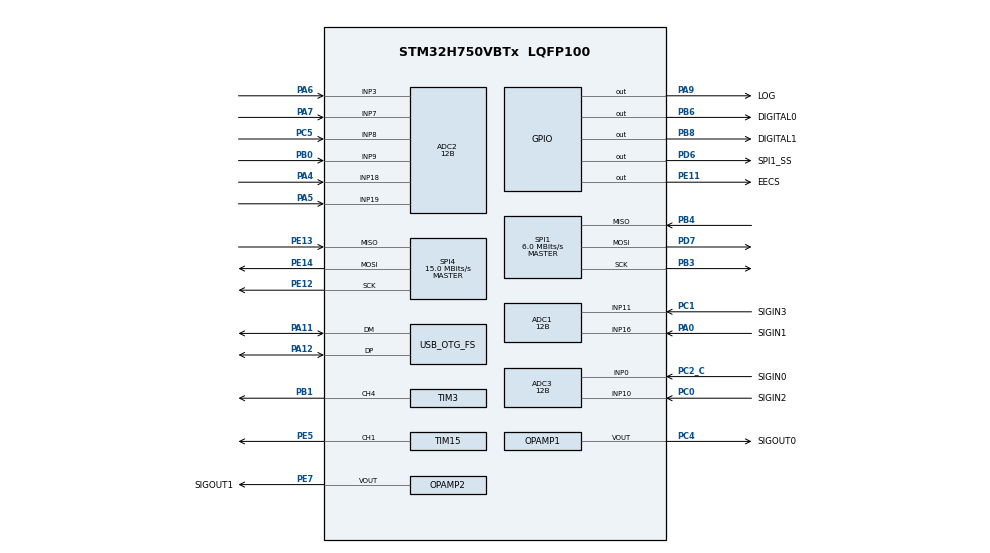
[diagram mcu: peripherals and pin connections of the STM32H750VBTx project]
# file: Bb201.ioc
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ADC1.Channel-0\#ChannelRegularConversion=ADC_CHANNEL_16
ADC1.Channel-3\#ChannelRegularConversion=ADC_CHANNEL_11
ADC1.ContinuousConvMode=DISABLE
ADC1.ConversionDataManagement=ADC_CONVERSIONDATA_DMA_CIRCULAR
ADC1.EOCSelection=ADC_EOC_SEQ_CONV
ADC1.ExternalTrigConv=ADC_EXTERNALTRIG_T6_TRGO
ADC1.NbrOfConversion=2
ADC1.NbrOfConversionFlag=1
ADC1.OffsetNumber-0\#ChannelRegularConversion=ADC_OFFSET_NONE
ADC1.OffsetNumber-3\#ChannelRegularConversion=ADC_OFFSET_NONE
ADC1.OffsetSignedSaturation-0\#ChannelRegularConversion=DISABLE
ADC1.Rank-0\#ChannelRegularConversion=1
ADC1.Rank-3\#ChannelRegularConversion=2
ADC1.Resolution=ADC_RESOLUTION_12B
ADC1.SamplingTime-0\#ChannelRegularConversion=ADC_SAMPLETIME_1CYCLE_5
ADC1.SamplingTime-3\#ChannelRegularConversion=ADC_SAMPLETIME_1CYCLE_5
ADC1.master=1
ADC2.Channel-0\#ChannelRegularConversion=ADC_CHANNEL_18
ADC2.Channel-1\#ChannelRegularConversion=ADC_CHANNEL_19
ADC2.Channel-2\#ChannelRegularConversion=ADC_CHANNEL_3
ADC2.Channel-3\#ChannelRegularConversion=ADC_CHANNEL_7
ADC2.Channel-4\#ChannelRegularConversion=ADC_CHANNEL_8
ADC2.Channel-5\#ChannelRegularConversion=ADC_CHANNEL_9
ADC2.ContinuousConvMode=DISABLE
ADC2.ConversionDataManagement=ADC_CONVERSIONDATA_DMA_CIRCULAR
ADC2.EOCSelection=ADC_EOC_SEQ_CONV
ADC2.ExternalTrigConv=ADC_EXTERNALTRIG_LPTIM3_OUT
ADC2.NbrOfConversion=6
ADC2.NbrOfConversionFlag=1
ADC2.OffsetNumber-0\#ChannelRegularConversion=ADC_OFFSET_NONE
ADC2.OffsetNumber-1\#ChannelRegularConversion=ADC_OFFSET_NONE
ADC2.OffsetNumber-2\#ChannelRegularConversion=ADC_OFFSET_NONE
ADC2.OffsetNumber-3\#ChannelRegularConversion=ADC_OFFSET_NONE
ADC2.OffsetNumber-4\#ChannelRegularConversion=ADC_OFFSET_NONE
ADC2.OffsetNumber-5\#ChannelRegularConversion=ADC_OFFSET_NONE
ADC2.OffsetSignedSaturation-0\#ChannelRegularConversion=DISABLE
ADC2.OffsetSignedSaturation-1\#ChannelRegularConversion=DISABLE
ADC2.OffsetSignedSaturation-2\#ChannelRegularConversion=DISABLE
ADC2.OffsetSignedSaturation-3\#ChannelRegularConversion=DISABLE
ADC2.OffsetSignedSaturation-4\#ChannelRegularConversion=DISABLE
ADC2.OffsetSignedSaturation-5\#ChannelRegularConversion=DISABLE
ADC2.OversamplingMode=DISABLE
ADC2.Rank-0\#ChannelRegularConversion=1
ADC2.Rank-1\#ChannelRegularConversion=2
ADC2.Rank-2\#ChannelRegularConversion=3
ADC2.Rank-3\#ChannelRegularConversion=4
ADC2.Rank-4\#ChannelRegularConversion=5
ADC2.Rank-5\#ChannelRegularConversion=6
ADC2.Resolution=ADC_RESOLUTION_12B
ADC2.SamplingTime-0\#ChannelRegularConversion=ADC_SAMPLETIME_2CYCLES_5
ADC2.SamplingTime-1\#ChannelRegularConversion=ADC_SAMPLETIME_2CYCLES_5
ADC2.SamplingTime-2\#ChannelRegularConversion=ADC_SAMPLETIME_2CYCLES_5
ADC2.SamplingTime-3\#ChannelRegularConversion=ADC_SAMPLETIME_2CYCLES_5
ADC2.SamplingTime-4\#ChannelRegularConversion=ADC_SAMPLETIME_2CYCLES_5
ADC2.SamplingTime-5\#ChannelRegularConversion=ADC_SAMPLETIME_2CYCLES_5
ADC3.Channel-0\#ChannelRegularConversion=ADC_CHANNEL_0
ADC3.Channel-3\#ChannelRegularConversion=ADC_CHANNEL_10
ADC3.ClockPrescaler=ADC_CLOCK_ASYNC_DIV1
ADC3.ContinuousConvMode=DISABLE
ADC3.ConversionDataManagement=ADC_CONVERSIONDATA_DMA_CIRCULAR
ADC3.EOCSelection=ADC_EOC_SEQ_CONV
ADC3.ExternalTrigConv=ADC_EXTERNALTRIG_T4_TRGO
ADC3.NbrOfConversion=2
ADC3.NbrOfConversionFlag=1
ADC3.OffsetNumber-0\#ChannelRegularConversion=ADC_OFFSET_NONE
ADC3.OffsetNumber-3\#ChannelRegularConversion=ADC_OFFSET_NONE
ADC3.OffsetSignedSaturation-0\#ChannelRegularConversion=DISABLE
ADC3.OversamplingMode=DISABLE
ADC3.Rank-0\#ChannelRegularConversion=1
ADC3.Rank-3\#ChannelRegularConversion=2
ADC3.Resolution=ADC_RESOLUTION_12B
ADC3.SamplingTime-0\#ChannelRegularConversion=ADC_SAMPLETIME_1CYCLE_5
ADC3.SamplingTime-3\#ChannelRegularConversion=ADC_SAMPLETIME_1CYCLE_5
ARM.CMSIS.5.7.0.CMSISJjCORE=true
ARM.CMSIS.5.7.0.CMSISJjDSP=Library
CORTEX_M7.AccessPermission-Cortex_Memory_Protection_Unit_Region0_Settings=MPU_REGION_FULL_ACCESS
CORTEX_M7.BaseAddress-Cortex_Memory_Protection_Unit_Region0_Settings=0x38000000
CORTEX_M7.CPU_DCache=Enabled
CORTEX_M7.CPU_ICache=Enabled
CORTEX_M7.DisableExec-Cortex_Memory_Protection_Unit_Region0_Settings=MPU_INSTRUCTION_ACCESS_DISABLE
CORTEX_M7.Enable-Cortex_Memory_Protection_Unit_Region0_Settings=MPU_REGION_ENABLE
CORTEX_M7.IsBufferable-Cortex_Memory_Protection_Unit_Region0_Settings=MPU_ACCESS_NOT_BUFFERABLE
CORTEX_M7.IsShareable-Cortex_Memory_Protection_Unit_Region0_Settings=MPU_ACCESS_NOT_SHAREABLE
CORTEX_M7.MPU_Control=MPU_PRIVILEGED_DEFAULT
CORTEX_M7.Size-Cortex_Memory_Protection_Unit_Region0_Settings=MPU_REGION_SIZE_64KB
DAC1.DAC_Channel-DAC_OUT2_Int=DAC_CHANNEL_2
DAC1.DAC_SampleAndHold-DAC_OUT1_Int=DAC_SAMPLEANDHOLD_DISABLE
DAC1.DAC_Trigger-DAC_OUT1_Int=DAC_TRIGGER_T4_TRGO
DAC1.DAC_Trigger-DAC_OUT2_Int=DAC_TRIGGER_T6_TRGO
DAC1.DAC_UserTrimming-DAC_OUT1_Int=DAC_TRIMMING_FACTORY
Dma.ADC1.0.Direction=DMA_PERIPH_TO_MEMORY
Dma.ADC1.0.EventEnable=DISABLE
Dma.ADC1.0.FIFOMode=DMA_FIFOMODE_DISABLE
Dma.ADC1.0.Instance=DMA2_Stream0
Dma.ADC1.0.MemDataAlignment=DMA_MDATAALIGN_HALFWORD
Dma.ADC1.0.MemInc=DMA_MINC_ENABLE
Dma.ADC1.0.Mode=DMA_CIRCULAR
Dma.ADC1.0.PeriphDataAlignment=DMA_PDATAALIGN_HALFWORD
Dma.ADC1.0.PeriphInc=DMA_PINC_DISABLE
Dma.ADC1.0.Polarity=HAL_DMAMUX_REQ_GEN_RISING
Dma.ADC1.0.Priority=DMA_PRIORITY_LOW
Dma.ADC1.0.RequestNumber=1
Dma.ADC1.0.SignalID=NONE
Dma.ADC1.0.SyncEnable=DISABLE
Dma.ADC1.0.SyncPolarity=HAL_DMAMUX_SYNC_NO_EVENT
Dma.ADC1.0.SyncRequestNumber=1
Dma.ADC1.0.SyncSignalID=NONE
Dma.ADC2.2.Direction=DMA_PERIPH_TO_MEMORY
Dma.ADC2.2.EventEnable=DISABLE
Dma.ADC2.2.FIFOMode=DMA_FIFOMODE_DISABLE
Dma.ADC2.2.Instance=DMA1_Stream2
Dma.ADC2.2.MemDataAlignment=DMA_MDATAALIGN_HALFWORD
Dma.ADC2.2.MemInc=DMA_MINC_ENABLE
Dma.ADC2.2.Mode=DMA_CIRCULAR
Dma.ADC2.2.PeriphDataAlignment=DMA_PDATAALIGN_HALFWORD
Dma.ADC2.2.PeriphInc=DMA_PINC_DISABLE
Dma.ADC2.2.Polarity=HAL_DMAMUX_REQ_GEN_RISING
Dma.ADC2.2.Priority=DMA_PRIORITY_LOW
Dma.ADC2.2.RequestNumber=1
Dma.ADC2.2.SignalID=NONE
Dma.ADC2.2.SyncEnable=DISABLE
Dma.ADC2.2.SyncPolarity=HAL_DMAMUX_SYNC_NO_EVENT
Dma.ADC2.2.SyncRequestNumber=1
Dma.ADC2.2.SyncSignalID=NONE
Dma.ADC3.3.Direction=DMA_PERIPH_TO_MEMORY
Dma.ADC3.3.EventEnable=DISABLE
Dma.ADC3.3.FIFOMode=DMA_FIFOMODE_DISABLE
Dma.ADC3.3.Instance=DMA1_Stream0
Dma.ADC3.3.MemDataAlignment=DMA_MDATAALIGN_HALFWORD
Dma.ADC3.3.MemInc=DMA_MINC_ENABLE
Dma.ADC3.3.Mode=DMA_CIRCULAR
Dma.ADC3.3.PeriphDataAlignment=DMA_PDATAALIGN_HALFWORD
Dma.ADC3.3.PeriphInc=DMA_PINC_DISABLE
Dma.ADC3.3.Polarity=HAL_DMAMUX_REQ_GEN_RISING
Dma.ADC3.3.Priority=DMA_PRIORITY_LOW
Dma.ADC3.3.RequestNumber=1
Dma.ADC3.3.SignalID=NONE
Dma.ADC3.3.SyncEnable=DISABLE
Dma.ADC3.3.SyncPolarity=HAL_DMAMUX_SYNC_NO_EVENT
Dma.ADC3.3.SyncRequestNumber=1
Dma.ADC3.3.SyncSignalID=NONE
Dma.DAC1_CH1.1.Direction=DMA_MEMORY_TO_PERIPH
Dma.DAC1_CH1.1.EventEnable=DISABLE
Dma.DAC1_CH1.1.FIFOMode=DMA_FIFOMODE_DISABLE
Dma.DAC1_CH1.1.Instance=DMA1_Stream1
Dma.DAC1_CH1.1.MemDataAlignment=DMA_MDATAALIGN_HALFWORD
Dma.DAC1_CH1.1.MemInc=DMA_MINC_ENABLE
Dma.DAC1_CH1.1.Mode=DMA_CIRCULAR
Dma.DAC1_CH1.1.PeriphDataAlignment=DMA_PDATAALIGN_HALFWORD
Dma.DAC1_CH1.1.PeriphInc=DMA_PINC_DISABLE
Dma.DAC1_CH1.1.Polarity=HAL_DMAMUX_REQ_GEN_RISING
Dma.DAC1_CH1.1.Priority=DMA_PRIORITY_LOW
Dma.DAC1_CH1.1.RequestNumber=1
Dma.DAC1_CH1.1.SignalID=NONE
Dma.DAC1_CH1.1.SyncEnable=DISABLE
Dma.DAC1_CH1.1.SyncPolarity=HAL_DMAMUX_SYNC_NO_EVENT
Dma.DAC1_CH1.1.SyncRequestNumber=1
Dma.DAC1_CH1.1.SyncSignalID=NONE
Dma.DAC1_CH2.4.Direction=DMA_MEMORY_TO_PERIPH
Dma.DAC1_CH2.4.EventEnable=DISABLE
Dma.DAC1_CH2.4.FIFOMode=DMA_FIFOMODE_DISABLE
Dma.DAC1_CH2.4.Instance=DMA2_Stream1
Dma.DAC1_CH2.4.MemDataAlignment=DMA_MDATAALIGN_HALFWORD
Dma.DAC1_CH2.4.MemInc=DMA_MINC_ENABLE
Dma.DAC1_CH2.4.Mode=DMA_CIRCULAR
Dma.DAC1_CH2.4.PeriphDataAlignment=DMA_PDATAALIGN_HALFWORD
Dma.DAC1_CH2.4.PeriphInc=DMA_PINC_DISABLE
Dma.DAC1_CH2.4.Polarity=HAL_DMAMUX_REQ_GEN_RISING
Dma.DAC1_CH2.4.Priority=DMA_PRIORITY_LOW
Dma.DAC1_CH2.4.RequestNumber=1
Dma.DAC1_CH2.4.SignalID=NONE
Dma.DAC1_CH2.4.SyncEnable=DISABLE
Dma.DAC1_CH2.4.SyncPolarity=HAL_DMAMUX_SYNC_NO_EVENT
Dma.DAC1_CH2.4.SyncRequestNumber=1
Dma.DAC1_CH2.4.SyncSignalID=NONE
Dma.Request0=ADC1
Dma.Request1=DAC1_CH1
Dma.Request2=ADC2
Dma.Request3=ADC3
Dma.Request4=DAC1_CH2
Dma.Request5=SPI4_RX
Dma.Request6=SPI4_TX
Dma.SPI4_RX.5.Direction=DMA_PERIPH_TO_MEMORY
Dma.SPI4_RX.5.EventEnable=DISABLE
Dma.SPI4_RX.5.FIFOMode=DMA_FIFOMODE_DISABLE
Dma.SPI4_RX.5.Instance=DMA1_Stream3
Dma.SPI4_RX.5.MemDataAlignment=DMA_MDATAALIGN_BYTE
Dma.SPI4_RX.5.MemInc=DMA_MINC_ENABLE
Dma.SPI4_RX.5.Mode=DMA_NORMAL
Dma.SPI4_RX.5.PeriphDataAlignment=DMA_PDATAALIGN_BYTE
Dma.SPI4_RX.5.PeriphInc=DMA_PINC_DISABLE
Dma.SPI4_RX.5.Polarity=HAL_DMAMUX_REQ_GEN_RISING
Dma.SPI4_RX.5.Priority=DMA_PRIORITY_LOW
Dma.SPI4_RX.5.RequestNumber=1
Dma.SPI4_RX.5.SignalID=NONE
Dma.SPI4_RX.5.SyncEnable=DISABLE
Dma.SPI4_RX.5.SyncPolarity=HAL_DMAMUX_SYNC_NO_EVENT
Dma.SPI4_RX.5.SyncRequestNumber=1
Dma.SPI4_RX.5.SyncSignalID=NONE
Dma.SPI4_TX.6.Direction=DMA_MEMORY_TO_PERIPH
Dma.SPI4_TX.6.EventEnable=DISABLE
Dma.SPI4_TX.6.FIFOMode=DMA_FIFOMODE_DISABLE
Dma.SPI4_TX.6.Instance=DMA1_Stream4
Dma.SPI4_TX.6.MemDataAlignment=DMA_MDATAALIGN_BYTE
Dma.SPI4_TX.6.MemInc=DMA_MINC_ENABLE
Dma.SPI4_TX.6.Mode=DMA_NORMAL
Dma.SPI4_TX.6.PeriphDataAlignment=DMA_PDATAALIGN_BYTE
Dma.SPI4_TX.6.PeriphInc=DMA_PINC_DISABLE
Dma.SPI4_TX.6.Polarity=HAL_DMAMUX_REQ_GEN_RISING
Dma.SPI4_TX.6.Priority=DMA_PRIORITY_LOW
Dma.SPI4_TX.6.RequestNumber=1
Dma.SPI4_TX.6.SignalID=NONE
Dma.SPI4_TX.6.SyncEnable=DISABLE
Dma.SPI4_TX.6.SyncPolarity=HAL_DMAMUX_SYNC_NO_EVENT
Dma.SPI4_TX.6.SyncRequestNumber=1
Dma.SPI4_TX.6.SyncSignalID=NONE
LPTIM3.ClockPrescaler=LPTIM_PRESCALER_DIV128
Mcu.Family=STM32H7
Mcu.Name=STM32H750VBTx
Mcu.Package=LQFP100
NVIC.DMA1_Stream0_IRQn=true\:0\:0\:false\:false\:true\:false\:true
NVIC.DMA1_Stream1_IRQn=true\:0\:0\:false\:false\:true\:false\:true
NVIC.DMA1_Stream2_IRQn=true\:0\:0\:false\:false\:true\:false\:true
NVIC.DMA1_Stream3_IRQn=true\:0\:0\:false\:false\:true\:false\:true
NVIC.DMA1_Stream4_IRQn=true\:0\:0\:false\:false\:true\:false\:true
NVIC.DMA2_Stream0_IRQn=true\:0\:0\:false\:false\:true\:false\:true
NVIC.DMA2_Stream1_IRQn=true\:0\:0\:false\:false\:true\:false\:true
NVIC.HASH_RNG_IRQn=true\:0\:0\:false\:false\:true\:true\:true
NVIC.OTG_FS_IRQn=true\:0\:0\:false\:false\:true\:false\:true
NVIC.PriorityGroup=NVIC_PRIORITYGROUP_4
NVIC.SPI4_IRQn=true\:0\:0\:false\:false\:true\:false\:true
NVIC.TIM15_IRQn=true\:0\:0\:false\:false\:true\:true\:true
NVIC.TIM7_IRQn=true\:0\:0\:false\:false\:true\:true\:true
OPAMP1.PowerMode=OPAMP_POWERMODE_HIGHSPEED
OPAMP1.SelfCalibration=Enable
OPAMP1.UserTrimming=OPAMP_TRIMMING_USER
OPAMP2.PowerMode=OPAMP_POWERMODE_HIGHSPEED
OPAMP2.SelfCalibration=Enable
OPAMP2.UserTrimming=OPAMP_TRIMMING_USER
PA0.GPIO_Label=SIGIN1
PA0.Mode=IN16-Single-Ended
PA0.Signal=ADC1_INP16
PA11.Mode=Device_Only
PA11.Signal=USB_OTG_FS_DM
PA12.Mode=Device_Only
PA12.Signal=USB_OTG_FS_DP
PA13\ (JTMS/SWDIO).Mode=Serial_Wire
PA13\ (JTMS/SWDIO).Signal=DEBUG_JTMS-SWDIO
PA14\ (JTCK/SWCLK).Mode=Serial_Wire
PA14\ (JTCK/SWCLK).Signal=DEBUG_JTCK-SWCLK
PA4.Signal=ADCx_INP18
PA5.Signal=ADCx_INP19
PA6.Signal=ADCx_INP3
PA7.Signal=ADCx_INP7
PA9.GPIO_Label=LOG
PA9.Signal=GPIO_Output
PB0.Signal=ADCx_INP9
PB1.Signal=S_TIM3_CH4
PB3\ (JTDO/TRACESWO).Mode=Full_Duplex_Master
PB3\ (JTDO/TRACESWO).Signal=SPI1_SCK
PB4\ (NJTRST).Mode=Full_Duplex_Master
PB4\ (NJTRST).Signal=SPI1_MISO
PB6.GPIO_Label=DIGITAL0
PB6.PinState=GPIO_PIN_SET
PB6.Signal=GPIO_Output
PB8.GPIO_Label=DIGITAL1
PB8.PinState=GPIO_PIN_SET
PB8.Signal=GPIO_Output
PC0.GPIO_Label=SIGIN2
PC0.Signal=ADCx_INP10
PC1.GPIO_Label=SIGIN3
PC1.Signal=ADCx_INP11
PC2_C.GPIO_Label=SIGIN0
PC2_C.Mode=IN0-Single-Ended
PC2_C.Signal=ADC3_INP0
PC4.GPIO_Label=SIGOUT0
PC4.Mode=Follower-DAC_OUT1-INP
PC4.Signal=OPAMP1_VOUT
PC5.Signal=ADCx_INP8
PD6.GPIO_Label=SPI1_SS
PD6.GPIO_PuPd=GPIO_PULLUP
PD6.GPIO_Speed=GPIO_SPEED_FREQ_HIGH
PD6.PinState=GPIO_PIN_SET
PD6.Signal=GPIO_Output
PD7.Mode=Full_Duplex_Master
PD7.Signal=SPI1_MOSI
PE11.GPIO_Label=EECS
PE11.Signal=GPIO_Output
PE12.Mode=Full_Duplex_Master
PE12.Signal=SPI4_SCK
PE13.Mode=Full_Duplex_Master
PE13.Signal=SPI4_MISO
PE14.Mode=Full_Duplex_Master
PE14.Signal=SPI4_MOSI
PE5.Signal=S_TIM15_CH1
PE7.GPIO_Label=SIGOUT1
PE7.Mode=Follower-DAC_OUT2-INP
PE7.Signal=OPAMP2_VOUT
PH0-OSC_IN\ (PH0).Mode=HSE-External-Oscillator
PH0-OSC_IN\ (PH0).Signal=RCC_OSC_IN
PH1-OSC_OUT\ (PH1).Mode=HSE-External-Oscillator
PH1-OSC_OUT\ (PH1).Signal=RCC_OSC_OUT
ProjectManager.HeapSize=0x200
ProjectManager.StackSize=0x400
ProjectManager.TargetToolchain=STM32CubeIDE
RCC.ADCCLockSelection=RCC_ADCCLKSOURCE_PLL3
RCC.ADCFreq_Value=40000000
RCC.APB1Freq_Value=120000000
RCC.APB2Freq_Value=120000000
RCC.APB3Freq_Value=120000000
RCC.APB4Freq_Value=120000000
RCC.CKPERSourceSelection=RCC_CLKPSOURCE_HSE
RCC.CortexFreq_Value=480000000
RCC.D1PPRE=RCC_APB3_DIV2
RCC.D2PPRE1=RCC_APB1_DIV2
RCC.D2PPRE2=RCC_APB2_DIV2
RCC.D3PPRE=RCC_APB4_DIV2
RCC.DIVM1=2
RCC.DIVM2=9
RCC.DIVM3=12
RCC.DIVN1=80
RCC.DIVN2=265
RCC.DIVN3=80
RCC.DIVP2=4
RCC.DIVQ1=20
RCC.DIVQ3=4
RCC.DIVR3=4
RCC.HCLKFreq_Value=240000000
RCC.HPRE=RCC_HCLK_DIV2
RCC.HSE_VALUE=24000000
RCC.LPTIM1CLockSelection=RCC_LPTIM1CLKSOURCE_CLKP
RCC.LPTIM2CLockSelection=RCC_LPTIM2CLKSOURCE_PLL2
RCC.LPTIM345CLockSelection=RCC_LPTIM345CLKSOURCE_PLL3
RCC.PLL2FRACN=4096
RCC.PLLFRACN=0
RCC.PLLSourceVirtual=RCC_PLLSOURCE_HSE
RCC.SPI123CLockSelection=RCC_SPI123CLKSOURCE_CLKP
RCC.SYSCLKFreq_VALUE=480000000
RCC.SYSCLKSource=RCC_SYSCLKSOURCE_PLLCLK
RCC.USBCLockSelection=RCC_USBCLKSOURCE_HSI48
RCC.USBFreq_Value=48000000
RNG.ClockErrorDetection=RNG_CED_DISABLE
SH.ADCx_INP10.0=ADC3_INP10,IN10-Single-Ended
SH.ADCx_INP11.0=ADC1_INP11,IN11-Single-Ended
SH.ADCx_INP18.0=ADC2_INP18,IN18-Single-Ended
SH.ADCx_INP19.0=ADC2_INP19,IN19-Single-Ended
SH.ADCx_INP3.0=ADC2_INP3,IN3-Single-Ended
SH.ADCx_INP7.0=ADC2_INP7,IN7-Single-Ended
SH.ADCx_INP8.0=ADC2_INP8,IN8-Single-Ended
SH.ADCx_INP9.0=ADC2_INP9,IN9-Single-Ended
SH.S_TIM15_CH1.0=TIM15_CH1,PWM Generation1 CH1
SH.S_TIM3_CH4.0=TIM3_CH4,PWM Generation4 CH4
SPI1.BaudRatePrescaler=SPI_BAUDRATEPRESCALER_4
SPI1.CalculateBaudRate=6.0 MBits/s
SPI1.DataSize=SPI_DATASIZE_8BIT
SPI1.Direction=SPI_DIRECTION_2LINES
SPI1.Mode=SPI_MODE_MASTER
SPI1.VirtualType=VM_MASTER
SPI4.BaudRatePrescaler=SPI_BAUDRATEPRESCALER_8
SPI4.CalculateBaudRate=15.0 MBits/s
SPI4.DataSize=SPI_DATASIZE_8BIT
SPI4.Direction=SPI_DIRECTION_2LINES
SPI4.Mode=SPI_MODE_MASTER
SPI4.VirtualType=VM_MASTER
TIM15.Channel-PWM\ Generation1\ CH1=TIM_CHANNEL_1
TIM15.Period=4000
TIM15.Prescaler=48000
TIM15.Pulse-PWM\ Generation1\ CH1=3800
TIM3.Channel-PWM\ Generation4\ CH4=TIM_CHANNEL_4
TIM3.Period=20000
TIM3.Prescaler=200
TIM3.Pulse-PWM\ Generation4\ CH4=10000
TIM4.Period=2500
TIM4.TIM_MasterOutputTrigger=TIM_TRGO_UPDATE
TIM6.Period=2500
TIM6.TIM_MasterOutputTrigger=TIM_TRGO_UPDATE
TIM7.Period=1000
TIM7.Prescaler=240
USB_DEVICE.CLASS_NAME_FS=CDC
USB_DEVICE.VirtualMode-CDC_FS=Cdc
USB_DEVICE.VirtualModeFS=Cdc_FS
USB_OTG_FS.VirtualMode=Device_Only
VP_ARM.CMSIS_VS_CMSISJjDSP_1.8.0_5.7.0.Mode=CMSISJjDSP
VP_DAC1_VS_DACI1.Mode=DAC_OUT1_Int
VP_DAC1_VS_DACI2.Mode=DAC_OUT2_Int
VP_LPTIM3_VS_LPTIM_counterModeInternalClock.Mode=Counts__internal_clock_event_00
VP_RNG_VS_RNG.Mode=RNG_Activate
VP_TIM4_VS_ClockSourceINT.Mode=Internal
VP_TIM6_VS_ClockSourceINT.Mode=Enable_Timer
VP_TIM7_VS_ClockSourceINT.Mode=Enable_Timer
VP_USB_DEVICE_VS_USB_DEVICE_CDC_FS.Mode=CDC_FS
board=custom

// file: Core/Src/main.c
/* USER CODE BEGIN Header */
/**
  ******************************************************************************
  * @file           : main.c
  * @brief          : Main program body
  ******************************************************************************
  * @attention
  *
  * <h2><center>&copy; Copyright (c) 2020 STMicroelectronics.
  * All rights reserved.</center></h2>
  *
  * This software component is licensed by ST under Ultimate Liberty license
  * SLA0044, the "License"; You may not use this file except in compliance with
  * the License. You may obtain a copy of the License at:
  *                             www.st.com/SLA0044
  *
  ******************************************************************************
  */
/* USER CODE END Header */
#include "main.h"
#include "usb_device.h"

/* USER CODE BEGIN Includes */
#include "usb_midi.h"
#include "fir.h"

/* USER CODE END Includes */

ADC_HandleTypeDef hadc1;
ADC_HandleTypeDef hadc2;
ADC_HandleTypeDef hadc3;
DMA_HandleTypeDef hdma_adc1;
DMA_HandleTypeDef hdma_adc2;
DMA_HandleTypeDef hdma_adc3;

DAC_HandleTypeDef hdac1;
DMA_HandleTypeDef hdma_dac1_ch1;
DMA_HandleTypeDef hdma_dac1_ch2;

LPTIM_HandleTypeDef hlptim3;

OPAMP_HandleTypeDef hopamp1;
OPAMP_HandleTypeDef hopamp2;

RNG_HandleTypeDef hrng;

SPI_HandleTypeDef hspi1;
SPI_HandleTypeDef hspi4;
DMA_HandleTypeDef hdma_spi4_rx;
DMA_HandleTypeDef hdma_spi4_tx;

TIM_HandleTypeDef htim3;
TIM_HandleTypeDef htim4;
TIM_HandleTypeDef htim6;
TIM_HandleTypeDef htim7;
TIM_HandleTypeDef htim15;

void SystemClock_Config(void);
static void MPU_Config(void);
static void MX_GPIO_Init(void);
static void MX_DMA_Init(void);
static void MX_DAC1_Init(void);
static void MX_OPAMP1_Init(void);
static void MX_ADC1_Init(void);
static void MX_ADC3_Init(void);
static void MX_TIM15_Init(void);
static void MX_OPAMP2_Init(void);
static void MX_ADC2_Init(void);
static void MX_LPTIM3_Init(void);
static void MX_TIM6_Init(void);
static void MX_TIM4_Init(void);
static void MX_SPI4_Init(void);
static void MX_RNG_Init(void);
static void MX_TIM7_Init(void);
static void MX_SPI1_Init(void);
static void MX_TIM3_Init(void);

int main(void)
{

  /* MPU Configuration--------------------------------------------------------*/
  MPU_Config();

  /* Enable I-Cache---------------------------------------------------------*/
  SCB_EnableICache();

  /* Enable D-Cache---------------------------------------------------------*/
  SCB_EnableDCache();

  /* MCU Configuration--------------------------------------------------------*/

  /* Reset of all peripherals, Initializes the Flash interface and the Systick. */
  HAL_Init();

  /* Configure the system clock */
  SystemClock_Config();

  /* Initialize all configured peripherals */
  MX_GPIO_Init();
  MX_DMA_Init();
  MX_DAC1_Init();
  MX_OPAMP1_Init();
  MX_ADC1_Init();
  MX_ADC3_Init();
  MX_TIM15_Init();
  MX_USB_DEVICE_Init();
  MX_OPAMP2_Init();
  MX_ADC2_Init();
  MX_LPTIM3_Init();
  MX_TIM6_Init();
  MX_TIM4_Init();
  MX_SPI4_Init();
  MX_RNG_Init();
  MX_TIM7_Init();
  MX_SPI1_Init();
  MX_TIM3_Init();
  /* USER CODE BEGIN 2 */
  bbSystemInit();

  /* fir test */
  //q15FirInit    (stage, AUDIO_BUFIN_CH0,(uint32_t )&audio_pipe[4], ffirCoeffs32,OUTCHANNEL_0);
  /* VCF Test */
  //VCFInit     (stage, AUDIO_BUFIN_CH0,(uint32_t )&audio_pipe[4],OUTCHANNEL_0);
  //ECHOInit    (stage, (uint32_t )&audio_pipe[4],AUDIO_BUFOUT_CH0,OUTCHANNEL_0);
  /* Osc test */
  /*
  ECHOInit    (stage, (uint32_t )&osc_output_buffer,(uint32_t )&audio_pipe[4],OUTCHANNEL_0);
  ECHOInit    (stage, (uint32_t )&audio_pipe[4],AUDIO_BUFOUT_CH0,OUTCHANNEL_0);
  ECHOInit(AUDIO_BUFIN_CH0, AUDIO_BUFOUT_CH0, OUTCHANNEL_0, stage);
  */
  //VCAInit(AUDIO_BUFIN_CH0, AUDIO_BUFOUT_CH0, (uint32_t )&control_buf.ain1, OUTCHANNEL_0, stage);
  //Mixer2CHInit(AUDIO_BUFIN_CH0, AUDIO_BUFIN_CH1, AUDIO_BUFOUT_CH0, (uint32_t )&control_buf.ain1, (uint32_t )&control_buf.ain2, OUTCHANNEL_0, stage);
  //Mixer2CHInit(AUDIO_BUFIN_CH0, (uint32_t )&osc_output_buffer, AUDIO_BUFOUT_CH0, (uint32_t )&control_buf.ain1, (uint32_t )&control_buf.ain2, OUTCHANNEL_0, stage);

  ECHOInit    ((uint32_t )&vco_buf[0],AUDIO_BUFOUT_CH0,OUTCHANNEL_0,stage);
  //ECHOInit    ((uint32_t )&lfo_buf[0],AUDIO_BUFOUT_CH0,OUTCHANNEL_0,stage);

  /* USER CODE END 2 */

  /* Infinite loop */
  /* USER CODE BEGIN WHILE */

  while (1)
  {
		if (( SystemFlags.audioin_buffer_ready_ch0 == 1 ) || ( SystemFlags.audioin_buffer_ready_ch1 == 1 ))
		{
			GetBufferIn();
			DoFunnelOut();
		}
		if ( SystemFlags.control_ready == 1 )
		{
			SystemFlags.control_ready = 0;
			DoControls();

		}
		if ( SystemFlags.systick_ready == 1)
		{
			SystemFlags.systick_ready = 0;
			//DoEnvelope();
			DoGraphicProcess();
		}
		UsbMidiCheck();
    /* USER CODE END WHILE */

  }
}

void SystemClock_Config(void)
{
  RCC_OscInitTypeDef RCC_OscInitStruct = {0};
  RCC_ClkInitTypeDef RCC_ClkInitStruct = {0};
  RCC_PeriphCLKInitTypeDef PeriphClkInitStruct = {0};

  /** Supply configuration update enable
  */
  HAL_PWREx_ConfigSupply(PWR_LDO_SUPPLY);
  /** Configure the main internal regulator output voltage
  */
  __HAL_PWR_VOLTAGESCALING_CONFIG(PWR_REGULATOR_VOLTAGE_SCALE0);

  while(!__HAL_PWR_GET_FLAG(PWR_FLAG_VOSRDY)) {}
  /** Macro to configure the PLL clock source
  */
  __HAL_RCC_PLL_PLLSOURCE_CONFIG(RCC_PLLSOURCE_HSE);
  /** Initializes the RCC Oscillators according to the specified parameters
  * in the RCC_OscInitTypeDef structure.
  */
  RCC_OscInitStruct.OscillatorType = RCC_OSCILLATORTYPE_HSI48|RCC_OSCILLATORTYPE_HSE;
  RCC_OscInitStruct.HSEState = RCC_HSE_ON;
  RCC_OscInitStruct.HSI48State = RCC_HSI48_ON;
  RCC_OscInitStruct.PLL.PLLState = RCC_PLL_ON;
  RCC_OscInitStruct.PLL.PLLSource = RCC_PLLSOURCE_HSE;
  RCC_OscInitStruct.PLL.PLLM = 2;
  RCC_OscInitStruct.PLL.PLLN = 80;
  RCC_OscInitStruct.PLL.PLLP = 2;
  RCC_OscInitStruct.PLL.PLLQ = 20;
  RCC_OscInitStruct.PLL.PLLR = 2;
  RCC_OscInitStruct.PLL.PLLRGE = RCC_PLL1VCIRANGE_3;
  RCC_OscInitStruct.PLL.PLLVCOSEL = RCC_PLL1VCOWIDE;
  RCC_OscInitStruct.PLL.PLLFRACN = 0;
  if (HAL_RCC_OscConfig(&RCC_OscInitStruct) != HAL_OK)
  {
    Error_Handler();
  }
  /** Initializes the CPU, AHB and APB buses clocks
  */
  RCC_ClkInitStruct.ClockType = RCC_CLOCKTYPE_HCLK|RCC_CLOCKTYPE_SYSCLK
                              |RCC_CLOCKTYPE_PCLK1|RCC_CLOCKTYPE_PCLK2
                              |RCC_CLOCKTYPE_D3PCLK1|RCC_CLOCKTYPE_D1PCLK1;
  RCC_ClkInitStruct.SYSCLKSource = RCC_SYSCLKSOURCE_PLLCLK;
  RCC_ClkInitStruct.SYSCLKDivider = RCC_SYSCLK_DIV1;
  RCC_ClkInitStruct.AHBCLKDivider = RCC_HCLK_DIV2;
  RCC_ClkInitStruct.APB3CLKDivider = RCC_APB3_DIV2;
  RCC_ClkInitStruct.APB1CLKDivider = RCC_APB1_DIV2;
  RCC_ClkInitStruct.APB2CLKDivider = RCC_APB2_DIV2;
  RCC_ClkInitStruct.APB4CLKDivider = RCC_APB4_DIV2;

  if (HAL_RCC_ClockConfig(&RCC_ClkInitStruct, FLASH_LATENCY_4) != HAL_OK)
  {
    Error_Handler();
  }
  PeriphClkInitStruct.PeriphClockSelection = RCC_PERIPHCLK_RNG|RCC_PERIPHCLK_SPI4
                              |RCC_PERIPHCLK_SPI1|RCC_PERIPHCLK_ADC
                              |RCC_PERIPHCLK_LPTIM3|RCC_PERIPHCLK_USB
                              |RCC_PERIPHCLK_CKPER;
  PeriphClkInitStruct.PLL3.PLL3M = 12;
  PeriphClkInitStruct.PLL3.PLL3N = 80;
  PeriphClkInitStruct.PLL3.PLL3P = 2;
  PeriphClkInitStruct.PLL3.PLL3Q = 4;
  PeriphClkInitStruct.PLL3.PLL3R = 4;
  PeriphClkInitStruct.PLL3.PLL3RGE = RCC_PLL3VCIRANGE_1;
  PeriphClkInitStruct.PLL3.PLL3VCOSEL = RCC_PLL3VCOMEDIUM;
  PeriphClkInitStruct.PLL3.PLL3FRACN = 0;
  PeriphClkInitStruct.CkperClockSelection = RCC_CLKPSOURCE_HSE;
  PeriphClkInitStruct.Spi123ClockSelection = RCC_SPI123CLKSOURCE_CLKP;
  PeriphClkInitStruct.Spi45ClockSelection = RCC_SPI45CLKSOURCE_D2PCLK1;
  PeriphClkInitStruct.RngClockSelection = RCC_RNGCLKSOURCE_HSI48;
  PeriphClkInitStruct.UsbClockSelection = RCC_USBCLKSOURCE_HSI48;
  PeriphClkInitStruct.Lptim345ClockSelection = RCC_LPTIM345CLKSOURCE_PLL3;
  PeriphClkInitStruct.AdcClockSelection = RCC_ADCCLKSOURCE_PLL3;
  if (HAL_RCCEx_PeriphCLKConfig(&PeriphClkInitStruct) != HAL_OK)
  {
    Error_Handler();
  }
  /** Enable USB Voltage detector
  */
  HAL_PWREx_EnableUSBVoltageDetector();
}

static void MX_ADC1_Init(void)
{

  ADC_MultiModeTypeDef multimode = {0};
  ADC_ChannelConfTypeDef sConfig = {0};

  /** Common config
  */
  hadc1.Instance = ADC1;
  hadc1.Init.ClockPrescaler = ADC_CLOCK_ASYNC_DIV1;
  hadc1.Init.Resolution = ADC_RESOLUTION_12B;
  hadc1.Init.ScanConvMode = ADC_SCAN_ENABLE;
  hadc1.Init.EOCSelection = ADC_EOC_SEQ_CONV;
  hadc1.Init.LowPowerAutoWait = DISABLE;
  hadc1.Init.ContinuousConvMode = DISABLE;
  hadc1.Init.NbrOfConversion = 2;
  hadc1.Init.DiscontinuousConvMode = DISABLE;
  hadc1.Init.ExternalTrigConv = ADC_EXTERNALTRIG_T6_TRGO;
  hadc1.Init.ExternalTrigConvEdge = ADC_EXTERNALTRIGCONVEDGE_RISING;
  hadc1.Init.ConversionDataManagement = ADC_CONVERSIONDATA_DMA_CIRCULAR;
  hadc1.Init.Overrun = ADC_OVR_DATA_PRESERVED;
  hadc1.Init.LeftBitShift = ADC_LEFTBITSHIFT_NONE;
  hadc1.Init.OversamplingMode = DISABLE;
  if (HAL_ADC_Init(&hadc1) != HAL_OK)
  {
    Error_Handler();
  }
  /** Configure the ADC multi-mode
  */
  multimode.Mode = ADC_MODE_INDEPENDENT;
  if (HAL_ADCEx_MultiModeConfigChannel(&hadc1, &multimode) != HAL_OK)
  {
    Error_Handler();
  }
  /** Configure Regular Channel
  */
  sConfig.Channel = ADC_CHANNEL_16;
  sConfig.Rank = ADC_REGULAR_RANK_1;
  sConfig.SamplingTime = ADC_SAMPLETIME_1CYCLE_5;
  sConfig.SingleDiff = ADC_SINGLE_ENDED;
  sConfig.OffsetNumber = ADC_OFFSET_NONE;
  sConfig.Offset = 0;
  sConfig.OffsetSignedSaturation = DISABLE;
  if (HAL_ADC_ConfigChannel(&hadc1, &sConfig) != HAL_OK)
  {
    Error_Handler();
  }
  /** Configure Regular Channel
  */
  sConfig.Channel = ADC_CHANNEL_11;
  sConfig.Rank = ADC_REGULAR_RANK_2;
  if (HAL_ADC_ConfigChannel(&hadc1, &sConfig) != HAL_OK)
  {
    Error_Handler();
  }

}

static void MX_ADC2_Init(void)
{

  ADC_ChannelConfTypeDef sConfig = {0};

  /** Common config
  */
  hadc2.Instance = ADC2;
  hadc2.Init.ClockPrescaler = ADC_CLOCK_ASYNC_DIV1;
  hadc2.Init.Resolution = ADC_RESOLUTION_12B;
  hadc2.Init.ScanConvMode = ADC_SCAN_ENABLE;
  hadc2.Init.EOCSelection = ADC_EOC_SEQ_CONV;
  hadc2.Init.LowPowerAutoWait = DISABLE;
  hadc2.Init.ContinuousConvMode = DISABLE;
  hadc2.Init.NbrOfConversion = 6;
  hadc2.Init.DiscontinuousConvMode = DISABLE;
  hadc2.Init.ExternalTrigConv = ADC_EXTERNALTRIG_LPTIM3_OUT;
  hadc2.Init.ExternalTrigConvEdge = ADC_EXTERNALTRIGCONVEDGE_RISING;
  hadc2.Init.ConversionDataManagement = ADC_CONVERSIONDATA_DMA_CIRCULAR;
  hadc2.Init.Overrun = ADC_OVR_DATA_PRESERVED;
  hadc2.Init.LeftBitShift = ADC_LEFTBITSHIFT_NONE;
  hadc2.Init.OversamplingMode = DISABLE;
  if (HAL_ADC_Init(&hadc2) != HAL_OK)
  {
    Error_Handler();
  }
  /** Configure Regular Channel
  */
  sConfig.Channel = ADC_CHANNEL_18;
  sConfig.Rank = ADC_REGULAR_RANK_1;
  sConfig.SamplingTime = ADC_SAMPLETIME_2CYCLES_5;
  sConfig.SingleDiff = ADC_SINGLE_ENDED;
  sConfig.OffsetNumber = ADC_OFFSET_NONE;
  sConfig.Offset = 0;
  sConfig.OffsetSignedSaturation = DISABLE;
  if (HAL_ADC_ConfigChannel(&hadc2, &sConfig) != HAL_OK)
  {
    Error_Handler();
  }
  /** Configure Regular Channel
  */
  sConfig.Channel = ADC_CHANNEL_19;
  sConfig.Rank = ADC_REGULAR_RANK_2;
  if (HAL_ADC_ConfigChannel(&hadc2, &sConfig) != HAL_OK)
  {
    Error_Handler();
  }
  /** Configure Regular Channel
  */
  sConfig.Channel = ADC_CHANNEL_3;
  sConfig.Rank = ADC_REGULAR_RANK_3;
  if (HAL_ADC_ConfigChannel(&hadc2, &sConfig) != HAL_OK)
  {
    Error_Handler();
  }
  /** Configure Regular Channel
  */
  sConfig.Channel = ADC_CHANNEL_7;
  sConfig.Rank = ADC_REGULAR_RANK_4;
  if (HAL_ADC_ConfigChannel(&hadc2, &sConfig) != HAL_OK)
  {
    Error_Handler();
  }
  /** Configure Regular Channel
  */
  sConfig.Channel = ADC_CHANNEL_8;
  sConfig.Rank = ADC_REGULAR_RANK_5;
  if (HAL_ADC_ConfigChannel(&hadc2, &sConfig) != HAL_OK)
  {
    Error_Handler();
  }
  /** Configure Regular Channel
  */
  sConfig.Channel = ADC_CHANNEL_9;
  sConfig.Rank = ADC_REGULAR_RANK_6;
  if (HAL_ADC_ConfigChannel(&hadc2, &sConfig) != HAL_OK)
  {
    Error_Handler();
  }

}

static void MX_ADC3_Init(void)
{

  ADC_ChannelConfTypeDef sConfig = {0};

  /** Common config
  */
  hadc3.Instance = ADC3;
  hadc3.Init.ClockPrescaler = ADC_CLOCK_ASYNC_DIV1;
  hadc3.Init.Resolution = ADC_RESOLUTION_12B;
  hadc3.Init.ScanConvMode = ADC_SCAN_ENABLE;
  hadc3.Init.EOCSelection = ADC_EOC_SEQ_CONV;
  hadc3.Init.LowPowerAutoWait = DISABLE;
  hadc3.Init.ContinuousConvMode = DISABLE;
  hadc3.Init.NbrOfConversion = 2;
  hadc3.Init.DiscontinuousConvMode = DISABLE;
  hadc3.Init.ExternalTrigConv = ADC_EXTERNALTRIG_T4_TRGO;
  hadc3.Init.ExternalTrigConvEdge = ADC_EXTERNALTRIGCONVEDGE_RISING;
  hadc3.Init.ConversionDataManagement = ADC_CONVERSIONDATA_DMA_CIRCULAR;
  hadc3.Init.Overrun = ADC_OVR_DATA_PRESERVED;
  hadc3.Init.LeftBitShift = ADC_LEFTBITSHIFT_NONE;
  hadc3.Init.OversamplingMode = DISABLE;
  if (HAL_ADC_Init(&hadc3) != HAL_OK)
  {
    Error_Handler();
  }
  /** Configure Regular Channel
  */
  sConfig.Channel = ADC_CHANNEL_0;
  sConfig.Rank = ADC_REGULAR_RANK_1;
  sConfig.SamplingTime = ADC_SAMPLETIME_1CYCLE_5;
  sConfig.SingleDiff = ADC_SINGLE_ENDED;
  sConfig.OffsetNumber = ADC_OFFSET_NONE;
  sConfig.Offset = 0;
  sConfig.OffsetSignedSaturation = DISABLE;
  if (HAL_ADC_ConfigChannel(&hadc3, &sConfig) != HAL_OK)
  {
    Error_Handler();
  }
  /** Configure Regular Channel
  */
  sConfig.Channel = ADC_CHANNEL_10;
  sConfig.Rank = ADC_REGULAR_RANK_2;
  if (HAL_ADC_ConfigChannel(&hadc3, &sConfig) != HAL_OK)
  {
    Error_Handler();
  }

}

static void MX_DAC1_Init(void)
{

  DAC_ChannelConfTypeDef sConfig = {0};

  /** DAC Initialization
  */
  hdac1.Instance = DAC1;
  if (HAL_DAC_Init(&hdac1) != HAL_OK)
  {
    Error_Handler();
  }
  /** DAC channel OUT1 config
  */
  sConfig.DAC_SampleAndHold = DAC_SAMPLEANDHOLD_DISABLE;
  sConfig.DAC_Trigger = DAC_TRIGGER_T4_TRGO;
  sConfig.DAC_OutputBuffer = DAC_OUTPUTBUFFER_DISABLE;
  sConfig.DAC_ConnectOnChipPeripheral = DAC_CHIPCONNECT_ENABLE;
  sConfig.DAC_UserTrimming = DAC_TRIMMING_FACTORY;
  if (HAL_DAC_ConfigChannel(&hdac1, &sConfig, DAC_CHANNEL_1) != HAL_OK)
  {
    Error_Handler();
  }
  /** DAC channel OUT2 config
  */
  sConfig.DAC_Trigger = DAC_TRIGGER_T6_TRGO;
  sConfig.DAC_ConnectOnChipPeripheral = DAC_CHIPCONNECT_ENABLE;
  if (HAL_DAC_ConfigChannel(&hdac1, &sConfig, DAC_CHANNEL_2) != HAL_OK)
  {
    Error_Handler();
  }

}

static void MX_LPTIM3_Init(void)
{

  hlptim3.Instance = LPTIM3;
  hlptim3.Init.Clock.Source = LPTIM_CLOCKSOURCE_APBCLOCK_LPOSC;
  hlptim3.Init.Clock.Prescaler = LPTIM_PRESCALER_DIV128;
  hlptim3.Init.Trigger.Source = LPTIM_TRIGSOURCE_SOFTWARE;
  hlptim3.Init.OutputPolarity = LPTIM_OUTPUTPOLARITY_HIGH;
  hlptim3.Init.UpdateMode = LPTIM_UPDATE_IMMEDIATE;
  hlptim3.Init.CounterSource = LPTIM_COUNTERSOURCE_INTERNAL;
  hlptim3.Init.Input1Source = LPTIM_INPUT1SOURCE_GPIO;
  if (HAL_LPTIM_Init(&hlptim3) != HAL_OK)
  {
    Error_Handler();
  }

}

static void MX_OPAMP1_Init(void)
{

  hopamp1.Instance = OPAMP1;
  hopamp1.Init.Mode = OPAMP_FOLLOWER_MODE;
  hopamp1.Init.NonInvertingInput = OPAMP_NONINVERTINGINPUT_DAC_CH;
  hopamp1.Init.PowerMode = OPAMP_POWERMODE_HIGHSPEED;
  hopamp1.Init.UserTrimming = OPAMP_TRIMMING_USER;
  hopamp1.Init.TrimmingValuePHighSpeed = 15;
  hopamp1.Init.TrimmingValueNHighSpeed = 15;
  if (HAL_OPAMP_Init(&hopamp1) != HAL_OK)
  {
    Error_Handler();
  }
  if (HAL_OPAMP_SelfCalibrate(&hopamp1) != HAL_OK)
  {
    Error_Handler();
  }

}

static void MX_OPAMP2_Init(void)
{

  hopamp2.Instance = OPAMP2;
  hopamp2.Init.Mode = OPAMP_FOLLOWER_MODE;
  hopamp2.Init.NonInvertingInput = OPAMP_NONINVERTINGINPUT_DAC_CH;
  hopamp2.Init.PowerMode = OPAMP_POWERMODE_HIGHSPEED;
  hopamp2.Init.UserTrimming = OPAMP_TRIMMING_USER;
  hopamp2.Init.TrimmingValuePHighSpeed = 15;
  hopamp2.Init.TrimmingValueNHighSpeed = 15;
  if (HAL_OPAMP_Init(&hopamp2) != HAL_OK)
  {
    Error_Handler();
  }
  if (HAL_OPAMP_SelfCalibrate(&hopamp2) != HAL_OK)
  {
    Error_Handler();
  }

}

static void MX_RNG_Init(void)
{

  hrng.Instance = RNG;
  hrng.Init.ClockErrorDetection = RNG_CED_DISABLE;
  if (HAL_RNG_Init(&hrng) != HAL_OK)
  {
    Error_Handler();
  }

}

static void MX_SPI1_Init(void)
{

  /* SPI1 parameter configuration*/
  hspi1.Instance = SPI1;
  hspi1.Init.Mode = SPI_MODE_MASTER;
  hspi1.Init.Direction = SPI_DIRECTION_2LINES;
  hspi1.Init.DataSize = SPI_DATASIZE_8BIT;
  hspi1.Init.CLKPolarity = SPI_POLARITY_LOW;
  hspi1.Init.CLKPhase = SPI_PHASE_1EDGE;
  hspi1.Init.NSS = SPI_NSS_SOFT;
  hspi1.Init.BaudRatePrescaler = SPI_BAUDRATEPRESCALER_2;
  hspi1.Init.FirstBit = SPI_FIRSTBIT_MSB;
  hspi1.Init.TIMode = SPI_TIMODE_DISABLE;
  hspi1.Init.CRCCalculation = SPI_CRCCALCULATION_DISABLE;
  hspi1.Init.CRCPolynomial = 0x0;
  hspi1.Init.NSSPMode = SPI_NSS_PULSE_ENABLE;
  hspi1.Init.NSSPolarity = SPI_NSS_POLARITY_LOW;
  hspi1.Init.FifoThreshold = SPI_FIFO_THRESHOLD_01DATA;
  hspi1.Init.TxCRCInitializationPattern = SPI_CRC_INITIALIZATION_ALL_ZERO_PATTERN;
  hspi1.Init.RxCRCInitializationPattern = SPI_CRC_INITIALIZATION_ALL_ZERO_PATTERN;
  hspi1.Init.MasterSSIdleness = SPI_MASTER_SS_IDLENESS_00CYCLE;
  hspi1.Init.MasterInterDataIdleness = SPI_MASTER_INTERDATA_IDLENESS_00CYCLE;
  hspi1.Init.MasterReceiverAutoSusp = SPI_MASTER_RX_AUTOSUSP_DISABLE;
  hspi1.Init.MasterKeepIOState = SPI_MASTER_KEEP_IO_STATE_DISABLE;
  hspi1.Init.IOSwap = SPI_IO_SWAP_DISABLE;
  if (HAL_SPI_Init(&hspi1) != HAL_OK)
  {
    Error_Handler();
  }

}

static void MX_SPI4_Init(void)
{

  /* SPI4 parameter configuration*/
  hspi4.Instance = SPI4;
  hspi4.Init.Mode = SPI_MODE_MASTER;
  hspi4.Init.Direction = SPI_DIRECTION_2LINES;
  hspi4.Init.DataSize = SPI_DATASIZE_8BIT;
  hspi4.Init.CLKPolarity = SPI_POLARITY_LOW;
  hspi4.Init.CLKPhase = SPI_PHASE_1EDGE;
  hspi4.Init.NSS = SPI_NSS_SOFT;
  hspi4.Init.BaudRatePrescaler = SPI_BAUDRATEPRESCALER_8;
  hspi4.Init.FirstBit = SPI_FIRSTBIT_MSB;
  hspi4.Init.TIMode = SPI_TIMODE_DISABLE;
  hspi4.Init.CRCCalculation = SPI_CRCCALCULATION_DISABLE;
  hspi4.Init.CRCPolynomial = 0x0;
  hspi4.Init.NSSPMode = SPI_NSS_PULSE_ENABLE;
  hspi4.Init.NSSPolarity = SPI_NSS_POLARITY_LOW;
  hspi4.Init.FifoThreshold = SPI_FIFO_THRESHOLD_01DATA;
  hspi4.Init.TxCRCInitializationPattern = SPI_CRC_INITIALIZATION_ALL_ZERO_PATTERN;
  hspi4.Init.RxCRCInitializationPattern = SPI_CRC_INITIALIZATION_ALL_ZERO_PATTERN;
  hspi4.Init.MasterSSIdleness = SPI_MASTER_SS_IDLENESS_00CYCLE;
  hspi4.Init.MasterInterDataIdleness = SPI_MASTER_INTERDATA_IDLENESS_00CYCLE;
  hspi4.Init.MasterReceiverAutoSusp = SPI_MASTER_RX_AUTOSUSP_DISABLE;
  hspi4.Init.MasterKeepIOState = SPI_MASTER_KEEP_IO_STATE_DISABLE;
  hspi4.Init.IOSwap = SPI_IO_SWAP_DISABLE;
  if (HAL_SPI_Init(&hspi4) != HAL_OK)
  {
    Error_Handler();
  }

}

static void MX_TIM3_Init(void)
{

  TIM_MasterConfigTypeDef sMasterConfig = {0};
  TIM_OC_InitTypeDef sConfigOC = {0};

  htim3.Instance = TIM3;
  htim3.Init.Prescaler = 200;
  htim3.Init.CounterMode = TIM_COUNTERMODE_UP;
  htim3.Init.Period = 20000;
  htim3.Init.ClockDivision = TIM_CLOCKDIVISION_DIV1;
  htim3.Init.AutoReloadPreload = TIM_AUTORELOAD_PRELOAD_DISABLE;
  if (HAL_TIM_PWM_Init(&htim3) != HAL_OK)
  {
    Error_Handler();
  }
  sMasterConfig.MasterOutputTrigger = TIM_TRGO_RESET;
  sMasterConfig.MasterSlaveMode = TIM_MASTERSLAVEMODE_DISABLE;
  if (HAL_TIMEx_MasterConfigSynchronization(&htim3, &sMasterConfig) != HAL_OK)
  {
    Error_Handler();
  }
  sConfigOC.OCMode = TIM_OCMODE_PWM1;
  sConfigOC.Pulse = 10000;
  sConfigOC.OCPolarity = TIM_OCPOLARITY_HIGH;
  sConfigOC.OCFastMode = TIM_OCFAST_DISABLE;
  if (HAL_TIM_PWM_ConfigChannel(&htim3, &sConfigOC, TIM_CHANNEL_4) != HAL_OK)
  {
    Error_Handler();
  }
  HAL_TIM_MspPostInit(&htim3);

}

static void MX_TIM4_Init(void)
{

  TIM_ClockConfigTypeDef sClockSourceConfig = {0};
  TIM_MasterConfigTypeDef sMasterConfig = {0};

  htim4.Instance = TIM4;
  htim4.Init.Prescaler = 0;
  htim4.Init.CounterMode = TIM_COUNTERMODE_UP;
  htim4.Init.Period = 2500;
  htim4.Init.ClockDivision = TIM_CLOCKDIVISION_DIV1;
  htim4.Init.AutoReloadPreload = TIM_AUTORELOAD_PRELOAD_DISABLE;
  if (HAL_TIM_Base_Init(&htim4) != HAL_OK)
  {
    Error_Handler();
  }
  sClockSourceConfig.ClockSource = TIM_CLOCKSOURCE_INTERNAL;
  if (HAL_TIM_ConfigClockSource(&htim4, &sClockSourceConfig) != HAL_OK)
  {
    Error_Handler();
  }
  sMasterConfig.MasterOutputTrigger = TIM_TRGO_UPDATE;
  sMasterConfig.MasterSlaveMode = TIM_MASTERSLAVEMODE_DISABLE;
  if (HAL_TIMEx_MasterConfigSynchronization(&htim4, &sMasterConfig) != HAL_OK)
  {
    Error_Handler();
  }

}

static void MX_TIM6_Init(void)
{

  TIM_MasterConfigTypeDef sMasterConfig = {0};

  htim6.Instance = TIM6;
  htim6.Init.Prescaler = 0;
  htim6.Init.CounterMode = TIM_COUNTERMODE_UP;
  htim6.Init.Period = 2500;
  htim6.Init.AutoReloadPreload = TIM_AUTORELOAD_PRELOAD_DISABLE;
  if (HAL_TIM_Base_Init(&htim6) != HAL_OK)
  {
    Error_Handler();
  }
  sMasterConfig.MasterOutputTrigger = TIM_TRGO_UPDATE;
  sMasterConfig.MasterSlaveMode = TIM_MASTERSLAVEMODE_DISABLE;
  if (HAL_TIMEx_MasterConfigSynchronization(&htim6, &sMasterConfig) != HAL_OK)
  {
    Error_Handler();
  }

}

static void MX_TIM7_Init(void)
{

  TIM_MasterConfigTypeDef sMasterConfig = {0};

  htim7.Instance = TIM7;
  htim7.Init.Prescaler = 240;
  htim7.Init.CounterMode = TIM_COUNTERMODE_UP;
  htim7.Init.Period = 1000;
  htim7.Init.AutoReloadPreload = TIM_AUTORELOAD_PRELOAD_DISABLE;
  if (HAL_TIM_Base_Init(&htim7) != HAL_OK)
  {
    Error_Handler();
  }
  sMasterConfig.MasterOutputTrigger = TIM_TRGO_RESET;
  sMasterConfig.MasterSlaveMode = TIM_MASTERSLAVEMODE_DISABLE;
  if (HAL_TIMEx_MasterConfigSynchronization(&htim7, &sMasterConfig) != HAL_OK)
  {
    Error_Handler();
  }

}

static void MX_TIM15_Init(void)
{

  TIM_MasterConfigTypeDef sMasterConfig = {0};
  TIM_OC_InitTypeDef sConfigOC = {0};
  TIM_BreakDeadTimeConfigTypeDef sBreakDeadTimeConfig = {0};

  htim15.Instance = TIM15;
  htim15.Init.Prescaler = 48000;
  htim15.Init.CounterMode = TIM_COUNTERMODE_UP;
  htim15.Init.Period = 4000;
  htim15.Init.ClockDivision = TIM_CLOCKDIVISION_DIV1;
  htim15.Init.RepetitionCounter = 0;
  htim15.Init.AutoReloadPreload = TIM_AUTORELOAD_PRELOAD_DISABLE;
  if (HAL_TIM_PWM_Init(&htim15) != HAL_OK)
  {
    Error_Handler();
  }
  sMasterConfig.MasterOutputTrigger = TIM_TRGO_RESET;
  sMasterConfig.MasterSlaveMode = TIM_MASTERSLAVEMODE_DISABLE;
  if (HAL_TIMEx_MasterConfigSynchronization(&htim15, &sMasterConfig) != HAL_OK)
  {
    Error_Handler();
  }
  sConfigOC.OCMode = TIM_OCMODE_PWM1;
  sConfigOC.Pulse = 3800;
  sConfigOC.OCPolarity = TIM_OCPOLARITY_HIGH;
  sConfigOC.OCNPolarity = TIM_OCNPOLARITY_HIGH;
  sConfigOC.OCFastMode = TIM_OCFAST_DISABLE;
  sConfigOC.OCIdleState = TIM_OCIDLESTATE_RESET;
  sConfigOC.OCNIdleState = TIM_OCNIDLESTATE_RESET;
  if (HAL_TIM_PWM_ConfigChannel(&htim15, &sConfigOC, TIM_CHANNEL_1) != HAL_OK)
  {
    Error_Handler();
  }
  sBreakDeadTimeConfig.OffStateRunMode = TIM_OSSR_DISABLE;
  sBreakDeadTimeConfig.OffStateIDLEMode = TIM_OSSI_DISABLE;
  sBreakDeadTimeConfig.LockLevel = TIM_LOCKLEVEL_OFF;
  sBreakDeadTimeConfig.DeadTime = 0;
  sBreakDeadTimeConfig.BreakState = TIM_BREAK_DISABLE;
  sBreakDeadTimeConfig.BreakPolarity = TIM_BREAKPOLARITY_HIGH;
  sBreakDeadTimeConfig.BreakFilter = 0;
  sBreakDeadTimeConfig.AutomaticOutput = TIM_AUTOMATICOUTPUT_DISABLE;
  if (HAL_TIMEx_ConfigBreakDeadTime(&htim15, &sBreakDeadTimeConfig) != HAL_OK)
  {
    Error_Handler();
  }
  HAL_TIM_MspPostInit(&htim15);

}

static void MX_DMA_Init(void)
{

  /* DMA controller clock enable */
  __HAL_RCC_DMA2_CLK_ENABLE();
  __HAL_RCC_DMA1_CLK_ENABLE();

  /* DMA interrupt init */
  /* DMA1_Stream0_IRQn interrupt configuration */
  HAL_NVIC_SetPriority(DMA1_Stream0_IRQn, 0, 0);
  HAL_NVIC_EnableIRQ(DMA1_Stream0_IRQn);
  /* DMA1_Stream1_IRQn interrupt configuration */
  HAL_NVIC_SetPriority(DMA1_Stream1_IRQn, 0, 0);
  HAL_NVIC_EnableIRQ(DMA1_Stream1_IRQn);
  /* DMA1_Stream2_IRQn interrupt configuration */
  HAL_NVIC_SetPriority(DMA1_Stream2_IRQn, 0, 0);
  HAL_NVIC_EnableIRQ(DMA1_Stream2_IRQn);
  /* DMA1_Stream3_IRQn interrupt configuration */
  HAL_NVIC_SetPriority(DMA1_Stream3_IRQn, 0, 0);
  HAL_NVIC_EnableIRQ(DMA1_Stream3_IRQn);
  /* DMA1_Stream4_IRQn interrupt configuration */
  HAL_NVIC_SetPriority(DMA1_Stream4_IRQn, 0, 0);
  HAL_NVIC_EnableIRQ(DMA1_Stream4_IRQn);
  /* DMA2_Stream0_IRQn interrupt configuration */
  HAL_NVIC_SetPriority(DMA2_Stream0_IRQn, 0, 0);
  HAL_NVIC_EnableIRQ(DMA2_Stream0_IRQn);
  /* DMA2_Stream1_IRQn interrupt configuration */
  HAL_NVIC_SetPriority(DMA2_Stream1_IRQn, 0, 0);
  HAL_NVIC_EnableIRQ(DMA2_Stream1_IRQn);

}

static void MX_GPIO_Init(void)
{
  GPIO_InitTypeDef GPIO_InitStruct = {0};

  /* GPIO Ports Clock Enable */
  __HAL_RCC_GPIOE_CLK_ENABLE();
  __HAL_RCC_GPIOH_CLK_ENABLE();
  __HAL_RCC_GPIOC_CLK_ENABLE();
  __HAL_RCC_GPIOA_CLK_ENABLE();
  __HAL_RCC_GPIOB_CLK_ENABLE();
  __HAL_RCC_GPIOD_CLK_ENABLE();

  /*Configure GPIO pin Output Level */
  HAL_GPIO_WritePin(EECS_GPIO_Port, EECS_Pin, GPIO_PIN_RESET);

  /*Configure GPIO pin Output Level */
  HAL_GPIO_WritePin(LOG_GPIO_Port, LOG_Pin, GPIO_PIN_RESET);

  /*Configure GPIO pin Output Level */
  HAL_GPIO_WritePin(SPI1_SS_GPIO_Port, SPI1_SS_Pin, GPIO_PIN_SET);

  /*Configure GPIO pin Output Level */
  HAL_GPIO_WritePin(GPIOB, DIGITAL0_Pin|DIGITAL1_Pin, GPIO_PIN_SET);

  /*Configure GPIO pin : EECS_Pin */
  GPIO_InitStruct.Pin = EECS_Pin;
  GPIO_InitStruct.Mode = GPIO_MODE_OUTPUT_PP;
  GPIO_InitStruct.Pull = GPIO_NOPULL;
  GPIO_InitStruct.Speed = GPIO_SPEED_FREQ_LOW;
  HAL_GPIO_Init(EECS_GPIO_Port, &GPIO_InitStruct);

  /*Configure GPIO pin : LOG_Pin */
  GPIO_InitStruct.Pin = LOG_Pin;
  GPIO_InitStruct.Mode = GPIO_MODE_OUTPUT_PP;
  GPIO_InitStruct.Pull = GPIO_NOPULL;
  GPIO_InitStruct.Speed = GPIO_SPEED_FREQ_LOW;
  HAL_GPIO_Init(LOG_GPIO_Port, &GPIO_InitStruct);

  /*Configure GPIO pin : SPI1_SS_Pin */
  GPIO_InitStruct.Pin = SPI1_SS_Pin;
  GPIO_InitStruct.Mode = GPIO_MODE_OUTPUT_PP;
  GPIO_InitStruct.Pull = GPIO_PULLUP;
  GPIO_InitStruct.Speed = GPIO_SPEED_FREQ_HIGH;
  HAL_GPIO_Init(SPI1_SS_GPIO_Port, &GPIO_InitStruct);

  /*Configure GPIO pins : DIGITAL0_Pin DIGITAL1_Pin */
  GPIO_InitStruct.Pin = DIGITAL0_Pin|DIGITAL1_Pin;
  GPIO_InitStruct.Mode = GPIO_MODE_OUTPUT_PP;
  GPIO_InitStruct.Pull = GPIO_NOPULL;
  GPIO_InitStruct.Speed = GPIO_SPEED_FREQ_LOW;
  HAL_GPIO_Init(GPIOB, &GPIO_InitStruct);

}

/* MPU Configuration */

void MPU_Config(void)
{
  MPU_Region_InitTypeDef MPU_InitStruct = {0};

  /* Disables the MPU */
  HAL_MPU_Disable();
  /** Initializes and configures the Region and the memory to be protected
  */
  MPU_InitStruct.Enable = MPU_REGION_ENABLE;
  MPU_InitStruct.Number = MPU_REGION_NUMBER0;
  MPU_InitStruct.BaseAddress = 0x38000000;
  MPU_InitStruct.Size = MPU_REGION_SIZE_64KB;
  MPU_InitStruct.SubRegionDisable = 0x0;
  MPU_InitStruct.TypeExtField = MPU_TEX_LEVEL0;
  MPU_InitStruct.AccessPermission = MPU_REGION_FULL_ACCESS;
  MPU_InitStruct.DisableExec = MPU_INSTRUCTION_ACCESS_DISABLE;
  MPU_InitStruct.IsShareable = MPU_ACCESS_NOT_SHAREABLE;
  MPU_InitStruct.IsCacheable = MPU_ACCESS_NOT_CACHEABLE;
  MPU_InitStruct.IsBufferable = MPU_ACCESS_NOT_BUFFERABLE;

  HAL_MPU_ConfigRegion(&MPU_InitStruct);
  /* Enables the MPU */
  HAL_MPU_Enable(MPU_PRIVILEGED_DEFAULT);

}

void Error_Handler(void)
{
  __disable_irq();
  while (1)
  {
  }
}

/************************ (C) COPYRIGHT STMicroelectronics *****END OF FILE****/
